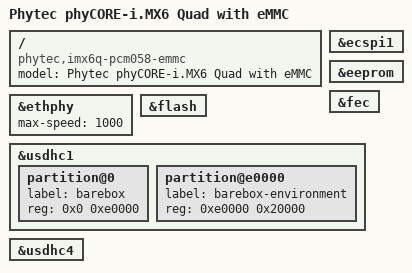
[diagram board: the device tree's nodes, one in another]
/*
 * Copyright 2015 Christian Hemp, Phytec Messtechnik GmbH
 *
 * The code contained herein is licensed under the GNU General Public
 * License. You may obtain a copy of the GNU General Public License
 * Version 2 or later at the following locations:
 *
 * http://www.opensource.org/licenses/gpl-license.html
 * http://www.gnu.org/copyleft/gpl.html
 */

/dts-v1/;

#include <arm/imx6q.dtsi>
#include "imx6q.dtsi"
#include "imx6qdl-phytec-phycore-som.dtsi"

/ {
	model = "Phytec phyCORE-i.MX6 Quad with eMMC";
	compatible = "phytec,imx6q-pcm058-emmc", "fsl,imx6q";
};

&ecspi1 {
	status = "okay";
};

&eeprom {
	status = "okay";
};

&ethphy {
	max-speed = <1000>;
};

&fec {
	status = "okay";
};

&flash {
	status = "okay";
};

&usdhc1 {
	status = "okay";

	#address-cells = <1>;
	#size-cells = <1>;

	partition@0 {
		label = "barebox";
		reg = <0x0 0xe0000>;
	};

	partition@e0000 {
		label = "barebox-environment";
		reg = <0xe0000 0x20000>;
	};
};

&usdhc4 {
	status = "okay";
};
